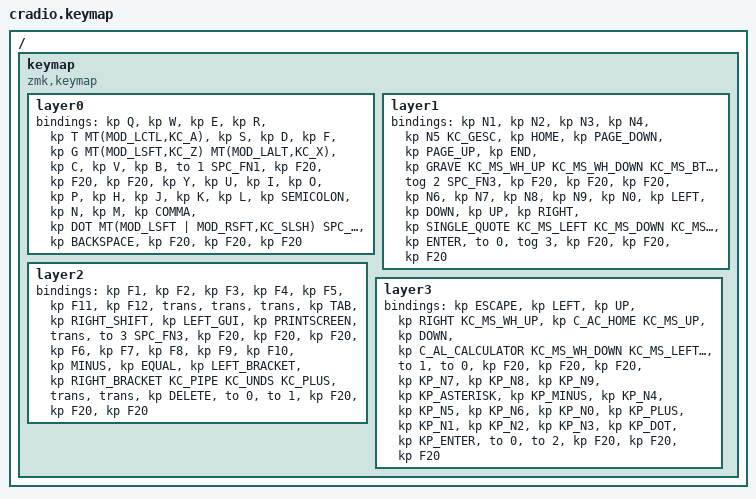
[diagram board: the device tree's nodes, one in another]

  /*
  * Copyright (c) 2020 The ZMK Contributors
  *
  * SPDX-License-Identifier: MIT
  */

  #include <behaviors.dtsi>
  #include <dt-bindings/zmk/keys.h>
  #include <dt-bindings/zmk/bt.h>
  #include <dt-bindings/zmk/ext_power.h>

  / {
    keymap {
      compatible = "zmk,keymap";
  layer0 {
          bindings = <
          &kp Q &kp W &kp E &kp R &kp T MT(MOD_LCTL,KC_A) &kp S &kp D &kp F &kp G MT(MOD_LSFT,KC_Z) MT(MOD_LALT,KC_X) &kp C &kp V &kp B &to 1 SPC_FN1 &kp F20 &kp F20 &kp F20 &kp Y &kp U &kp I &kp O &kp P &kp H &kp J &kp K &kp L &kp SEMICOLON &kp N &kp M &kp COMMA &kp DOT MT(MOD_LSFT | MOD_RSFT,KC_SLSH) SPC_FN3 &kp BACKSPACE &kp F20 &kp F20 &kp F20
          >;
        };layer1 {
          bindings = <
          &kp N1 &kp N2 &kp N3 &kp N4 &kp N5 KC_GESC &kp HOME &kp PAGE_DOWN &kp PAGE_UP &kp END &kp GRAVE KC_MS_WH_UP KC_MS_WH_DOWN KC_MS_BTN1 KC_MS_BTN2 &tog 2 SPC_FN3 &kp F20 &kp F20 &kp F20 &kp N6 &kp N7 &kp N8 &kp N9 &kp N0 &kp LEFT &kp DOWN &kp UP &kp RIGHT &kp SINGLE_QUOTE KC_MS_LEFT KC_MS_DOWN KC_MS_UP KC_MS_RIGHT &kp ENTER &to 0 &tog 3 &kp F20 &kp F20 &kp F20
          >;
        };layer2 {
          bindings = <
          &kp F1 &kp F2 &kp F3 &kp F4 &kp F5 &kp F11 &kp F12 &trans &trans &trans &kp TAB &kp RIGHT_SHIFT &kp LEFT_GUI &kp PRINTSCREEN &trans &to 3 SPC_FN3 &kp F20 &kp F20 &kp F20 &kp F6 &kp F7 &kp F8 &kp F9 &kp F10 &kp MINUS &kp EQUAL &kp LEFT_BRACKET &kp RIGHT_BRACKET KC_PIPE KC_UNDS KC_PLUS &trans &trans &kp DELETE &to 0 &to 1 &kp F20 &kp F20 &kp F20
          >;
        };layer3 {
          bindings = <
          &kp ESCAPE &kp LEFT &kp UP &kp RIGHT KC_MS_WH_UP &kp C_AC_HOME KC_MS_UP &kp DOWN &kp C_AL_CALCULATOR KC_MS_WH_DOWN KC_MS_LEFT KC_MS_DOWN KC_MS_RIGHT KC_MS_BTN1 KC_MS_BTN2 &to 1 &to 0 &kp F20 &kp F20 &kp F20 &kp KP_N7 &kp KP_N8 &kp KP_N9 &kp KP_ASTERISK &kp KP_MINUS &kp KP_N4 &kp KP_N5 &kp KP_N6 &kp KP_N0 &kp KP_PLUS &kp KP_N1 &kp KP_N2 &kp KP_N3 &kp KP_DOT &kp KP_ENTER &to 0 &to 2 &kp F20 &kp F20 &kp F20
          >;
        };
    };
  };
  
